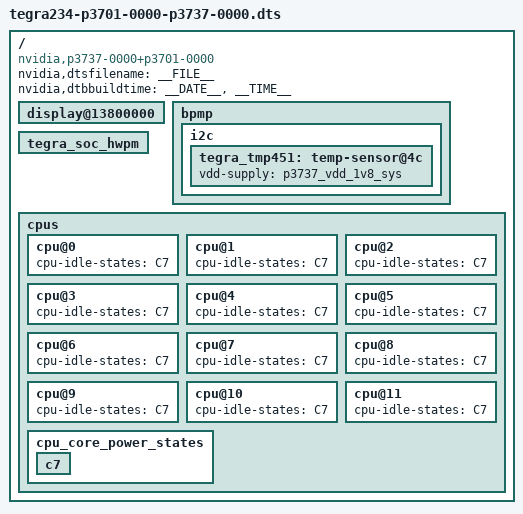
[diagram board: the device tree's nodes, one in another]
/*
 * Top level DTS file for CVM:P3701-0000 and CVB:P3737-0000.
 *
 * Copyright (c) 2021, NVIDIA CORPORATION.  All rights reserved.
 *
 * This program is free software; you can redistribute it and/or modify
 * it under the terms of the GNU General Public License as published by
 * the Free Software Foundation; version 2 of the License.
 *
 * This program is distributed in the hope that it will be useful, but WITHOUT
 * ANY WARRANTY; without even the implied warranty of MERCHANTABILITY or
 * FITNESS FOR A PARTICULAR PURPOSE.  See the GNU General Public License for
 * more details.
 */

/dts-v1/;
#include "cvm/tegra234-p3701-0000.dtsi"
#include "cvb/tegra234-p3737-0000-a00.dtsi"
#include "tegra234-power-tree-p3701-0000-p3737-0000.dtsi"
#include "tegra234-dcb-p3701-0000-a02-p3737-0000-a01.dtsi"
#include <tegra234-soc/mods-simple-bus.dtsi>
#include "cvb/tegra234-p3737-0000-camera-imx274-dual.dtsi"
#include <t234-common-cvm/tegra234-thermal.dtsi>
#include <tegra234-soc/tegra234-cpuidle.dtsi>

/ {
	nvidia,dtsfilename = __FILE__;
	nvidia,dtbbuildtime = __DATE__, __TIME__;

	compatible = "nvidia,p3737-0000+p3701-0000", "nvidia,tegra234", "nvidia,tegra23x";

	display@13800000 {
		status = "okay";
	};

	bpmp {
		i2c {
			tegra_tmp451: temp-sensor@4c {
				vdd-supply = <&p3737_vdd_1v8_sys>;
			};
		};
	};

	tegra_soc_hwpm {
                status = "okay";
        };

	cpus {
		cpu@0 {
			cpu-idle-states = <&C7>;
		};

		cpu@1 {
			cpu-idle-states = <&C7>;
		};

		cpu@2 {
			cpu-idle-states = <&C7>;
		};

		cpu@3 {
			cpu-idle-states = <&C7>;
		};

		cpu@4 {
			cpu-idle-states = <&C7>;
		};

		cpu@5 {
			cpu-idle-states = <&C7>;
		};

		cpu@6 {
			cpu-idle-states = <&C7>;
		};

		cpu@7 {
			cpu-idle-states = <&C7>;
		};

		cpu@8 {
			cpu-idle-states = <&C7>;
		};

		cpu@9 {
			cpu-idle-states = <&C7>;
		};

		cpu@10 {
			cpu-idle-states = <&C7>;
		};

		cpu@11 {
			cpu-idle-states = <&C7>;
		};

		cpu_core_power_states {
			c7 {
				status = "okay";
			};
		};
	};
};

#include "tegra234-disabled_nodes.dtsi"
